# ISP register map
Vendor: Texas Instruments
Peripheral module from a debugger description file (folder omap34xx).
Registers are 32-bit, read-write, reset 0x0 unless marked. A register's access mark holds for its fields unless they carry their own. Offsets are as the file gives them; lines under a group give offsets from that group; [hi:lo] are bit positions; {n}, {i} and the like mark numbered series; 'fields as' and 'values as' point back to an identical list; <NAME> marks a mode.

## ISP
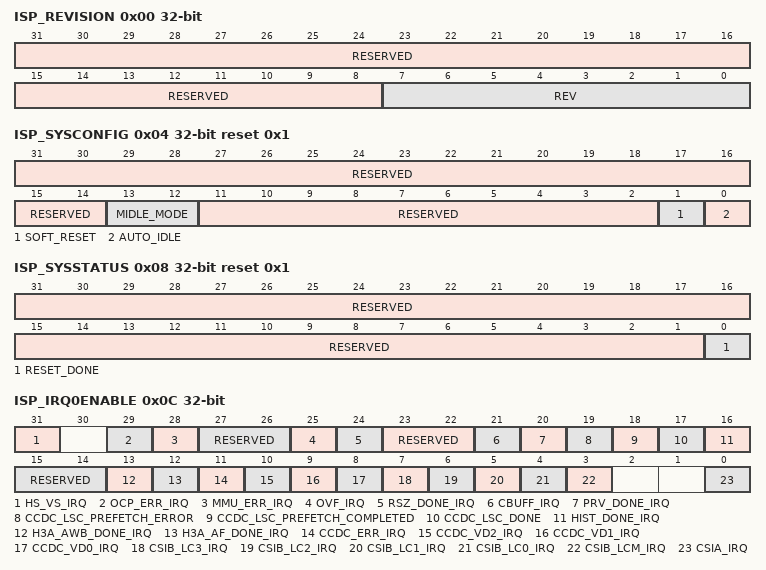
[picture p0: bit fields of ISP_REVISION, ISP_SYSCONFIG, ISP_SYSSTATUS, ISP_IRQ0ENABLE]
0x00 ISP_REVISION ro (reset mask 0xFFFFFF00) — ISP REVISION REGISTER This register contains the IP revision code in binary coded digital. For example, we have: 0x01 = revision 0.1 and 0x21 = revision 2.1
  [31:8] RESERVED — Write 0s for future compatibility.Reads returns 0.
  [7:0] REV — IP revision. [7:4] major revision[3:0] minor revision
0x04 ISP_SYSCONFIG reset 0x1 — ISP SYSTEM CONFIGURATION REGISTER
  [31:14] RESERVED — Write 0s for future compatibility.Reads returns 0.
  [13:12] MIDLE_MODE — Master interface power management, MSTANDBY/WAIT protocol.
    0=Force-standby: the MSTANDBY signal is only asserted to the power and reset clock manager when the module is disabled; 1=No-standby: the MSTANDBY signal is never asserted to the power and reset clock manager; 2=Smart-standby: the MSTANDBY signal is asserted to the power and reset clock manager based on the internal activity of the module. The ISP clocks are not disabled during smart standby.
  [11:2] RESERVED — Write 0s for future compatibility.Reads returns 0.
  [1] SOFT_RESET — Software reset. Set the bit to 1 to trigger the module reset. The bit is automatically reset be the HW. During reads return 0.
    0=Normal mode; 1=The module is reset
  [0] AUTO_IDLE — Internal interconnect and functional clock gating strategy
    0=Interconnect and functional clock is free running; 1=Automatic interface clock gating strategy is applied based on the Interconnect interface activity for interface clock and on the functional activity for functional clocks
0x08 ISP_SYSSTATUS ro reset 0x1 — ISP SYSTEM STATUS REGISTER
  [31:1] RESERVED — Write 0s for future compatibility.Reads returns 0.
  [0] RESET_DONE — Internal reset monitoring
    0=Internal module reset is ongoing; 1=Reset completed
0x0C ISP_IRQ0ENABLE — INTERRUPT ENABLE REGISTER TO MCU. IRQ0 STATUS LINE. The same events are mapped in IRQ1. However, one event should be mapped to only one target.
  [31] HS_VS_IRQ — HS or VS synchro event This event is triggered if a rising or falling edge is detected on the HS or VS signal. The rising or falling edge and the HS or VS signal selection is chosen with the ISP_CTRL.SYNC_DTECT bit field.
    0=Event is masked; 1=Event generates an interrupt when it occurs
  [29] OCP_ERR_IRQ — ISP Interconnect error. This event is triggered when an Interconnect error occurs: SResp = ERR.
    values as HS_VS_IRQ
  [28] MMU_ERR_IRQ — MMU error.
    values as HS_VS_IRQ
  [27:26] RESERVED — Write 0s for future compatibility.Reads returns 0.
  [25] OVF_IRQ — Central Resource SBL overflow This event is triggered when one of the buffer in the central resource SBL overflows.
    values as HS_VS_IRQ
  [24] RSZ_DONE_IRQ — RESIZER module - resizer processing done event. This event is triggered at the end of the frame when the processing is completed for the current frame.
    values as HS_VS_IRQ
  [23:22] RESERVED — Write 0s for future compatibility.Reads returns 0.
  [21] CBUFF_IRQ — Circular buffer interrupt
    values as HS_VS_IRQ
  [20] PRV_DONE_IRQ — PREVIEW module - processing done event. This event is triggered at the end of the frame when the processing is completed for the current frame.
    values as HS_VS_IRQ
  [19] CCDC_LSC_PREFETCH_ERROR — The prefetch error indicates when the gain table was read to slowly from SDRAM. When this event is pending the module goes into transparent mode (output=input). Normal operation can be resumed at the start of the next frame after1) clearing this event2) disabling the LSC module3) enabling it
    values as HS_VS_IRQ
  [18] CCDC_LSC_PREFETCH_COMPLETED — Indicates current state of the prefetch buffer. Can be used to start sending the data once the buffer is full to minimize the risk of an underflow. This event is triggered when the buffer contains 3 full paxel rows. It can be used to minimize buffer underflow risks.
    values as HS_VS_IRQ
  [17] CCDC_LSC_DONE — The event is triggered when the internal state of LSCtoggles from BUSY to IDLE.
    values as HS_VS_IRQ
  [16] HIST_DONE_IRQ — HIST module - processing done event. This event is triggered at the end of the frame when the processing is completed for the current frame.
    values as HS_VS_IRQ
  [15:14] RESERVED — Write 0s for future compatibility.Reads returns 0.
  [13] H3A_AWB_DONE_IRQ — H3A module - auto exposure and auto white balance processing done event. This event is triggered at the end of the frame when the processing is completed for the current frame.
    values as HS_VS_IRQ
  [12] H3A_AF_DONE_IRQ — H3A module - autofocus processing done event. This event is triggered at the end of the frame when the processing is completed for the current frame.
    values as HS_VS_IRQ
  [11] CCDC_ERR_IRQ — CCDC module - faulty pixel correction memory underflow
    values as HS_VS_IRQ
  [10] CCDC_VD2_IRQ — CCDC module - programmable event 2
    values as HS_VS_IRQ
  [9] CCDC_VD1_IRQ — CCDC module - programmable event 1.
    values as HS_VS_IRQ
  [8] CCDC_VD0_IRQ — CCDC module - programmable event 0.
    values as HS_VS_IRQ
  [7] CSIB_LC3_IRQ — CSI1/CCP2B receiver module - event on logical channel 3.
    values as HS_VS_IRQ
  [6] CSIB_LC2_IRQ — CSI1/CCP2B receiver module - event on logical channel 2
    values as HS_VS_IRQ
  [5] CSIB_LC1_IRQ — CSI1/CCP2B receiver module - event on logical channel 1
    values as HS_VS_IRQ
  [4] CSIB_LC0_IRQ — CSI1/CCP2B receiver module - event on logical channel 0
    values as HS_VS_IRQ
  [3] CSIB_LCM_IRQ — CSI1/CCP2B RECEIVER module - event on memory channel.
    values as HS_VS_IRQ
  [0] CSIA_IRQ — CSIA_RECEIVER module event.
    values as HS_VS_IRQ
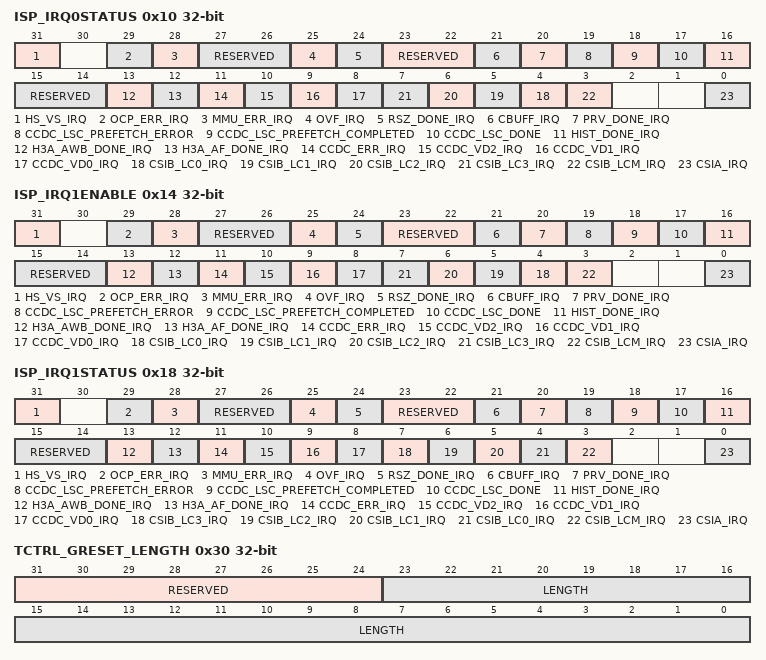
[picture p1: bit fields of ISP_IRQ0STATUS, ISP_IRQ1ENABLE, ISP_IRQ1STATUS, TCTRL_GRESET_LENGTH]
0x10 ISP_IRQ0STATUS access not given — INTERRUPT STATUS REGISTER TO MCU. IRQ0 STATUS LINE.
  [31] HS_VS_IRQ — HS or VS synchro event READS:0: event is false1: event is true WRITES0: status bit unchanged1: status bit reset (access R/W/1toClr)
  [29] OCP_ERR_IRQ — ISP Interconnect error. READS:0: event is false1: event is true WRITES0: status bit unchanged1: status bit reset (access R/W/1toClr)
  [28] MMU_ERR_IRQ — MMU error. If event is true, one needs to read the MMU_IRQSTATUS register to know the event source. Write in MMU_IRQSTATUS to clear the bit. READS:0: event is false1: event is true (access R/W/1toClr)
  [27:26] RESERVED — Write 0s for future compatibility.Reads returns 0. (access R/W/1toClr)
  [25] OVF_IRQ — Central Resource SBL overflow If event is true, one needs to check the SBL_PCR register to know the source. One needs to clear the SBL_PCR register first before clearing this bit. READS:0: event is false1: event is true WRITES0: status bit unchanged1: status bit reset (access R/W/1toClr)
  [24] RSZ_DONE_IRQ — RESIZER module - resizer processing done event. READS:0: event is false1: event is true WRITES0: status bit unchanged1: status bit reset (access R/W/1toClr)
    values as ISP_IRQ0ENABLE.HS_VS_IRQ
  [23:22] RESERVED — Write 0s for future compatibility.Reads returns 0. (access R/W/1toClr)
  [21] CBUFF_IRQ — A circular buffer event is pending. Check submodule's interrupt status register. READS:0: event is false1: event is true WRITES0: status bit unchanged1: status bit reset (access R/W/1toClr)
  [20] PRV_DONE_IRQ — PREVIEW module - processing done event. READS:0: event is false1: event is true WRITES0: status bit unchanged1: status bit reset (access R/W/1toClr)
  [19] CCDC_LSC_PREFETCH_ERROR — The prefetch error indicates when the gain table was read to slowly from SDRAM. READS:0: event is false1: event is true WRITES0: status bit unchanged1: status bit reset (access R/W/1toClr)
  [18] CCDC_LSC_PREFETCH_COMPLETED — Indicates current state of the prefetch buffer. READS:0: event is false1: event is true WRITES0: status bit unchanged1: status bit reset (access R/W/1toClr)
  [17] CCDC_LSC_DONE — The event is triggered when the internal state of LSC toggles from BUSY to IDLE. READS:0: event is false1: event is true WRITES0: status bit unchanged1: status bit reset (access R/W/1toClr)
  [16] HIST_DONE_IRQ — HIST module - processing done event.READS:0: event is false1: event is true WRITES0: status bit unchanged1: status bit reset (access R/W/1toClr)
  [15:14] RESERVED — Write 0s for future compatibility.Reads returns 0. (access R/W/1toClr)
  [13] H3A_AWB_DONE_IRQ — H3A module - auto exposure and auto white balance processing done event. READS:0: event is false1: event is true WRITES0: status bit unchanged1: status bit reset (access R/W/1toClr)
  [12] H3A_AF_DONE_IRQ — H3A module - autofocus processing done event. READS:0: event is false1: event is true WRITES0: status bit unchanged1: status bit reset (access R/W/1toClr)
  [11] CCDC_ERR_IRQ — CCDC module - faulty pixel correction memory underflow If event is true, one needs to clear the CCDC_FPC.FPERR bit first before clearing this bit. READS:0: event is false1: event is true WRITES0: status bit unchanged1: status bit reset (access R/W/1toClr)
  [10] CCDC_VD2_IRQ — CCDC module - programmable event 2 READS:0: event is false1: event is true WRITES0: status bit unchanged1: status bit reset (access R/W/1toClr)
  [9] CCDC_VD1_IRQ — CCDC module - programmable event 1. READS:0: event is false1: event is true WRITES0: status bit unchanged1: status bit reset (access R/W/1toClr)
  [8] CCDC_VD0_IRQ — CCDC module - programmable event 0. READS:0: event is false1: event is true WRITES0: status bit unchanged1: status bit reset (access R/W/1toClr)
  [n+4] CSIB_LC{n}_IRQ (n=0..3) — CSI1/CCP2B receiver module - event on logical channel {n}. READS:0: event is false1: event is true WRITES0: status bit unchanged1: status bit reset (access R/W/1toClr)
  [3] CSIB_LCM_IRQ — CSI1/CCP2B receiver module - event on memory channel. READS:0: event is false1: event is true WRITES0: status bit unchanged1: status bit reset (access R/W/1toClr)
  [0] CSIA_IRQ — CSIA RECEIVER module event. If event is true, one needs to read the CSIA_IRQSTATUS register to know the event source. Write in CSIA_IRQSTATUS to clear the bit. READS:0: event is false1: event is true WRITES0: status bit unchanged1: status bit reset (access R/W/1toClr)
0x14 ISP_IRQ1ENABLE — INTERRUPT ENABLE REGISTER TO DSP. IRQ1 STATUS LINE. The same events are mapped in IRQ0. However, one event should be mapped to only one target.
  [31] HS_VS_IRQ — HS or VS synchro event This event is triggered if a rising or falling edge is detected on the HS or VS signal. The rising or falling edge and the HS or VS signal selection is chosen with the ISP_CTRL.SYNC_DTECT bit field.
    values as ISP_IRQ0ENABLE.HS_VS_IRQ
  [29] OCP_ERR_IRQ — ISP Interconnect error. This event is triggered when an Interconnect error occurs: SResp = ERR.
    values as ISP_IRQ0ENABLE.HS_VS_IRQ
  [28] MMU_ERR_IRQ — MMU error.
    values as ISP_IRQ0ENABLE.HS_VS_IRQ
  [27:26] RESERVED — Write 0s for future compatibility.Reads returns 0.
  [25] OVF_IRQ — Central Resource SBL overflow This event is triggered when one of the buffer in the central resource SBL overflows.
    values as ISP_IRQ0ENABLE.HS_VS_IRQ
  [24] RSZ_DONE_IRQ — RESIZER module - resizer processing done event. This event is triggered at the end of the frame when the processing is completed for the current frame.
    values as ISP_IRQ0ENABLE.HS_VS_IRQ
  [23:22] RESERVED — Write 0s for future compatibility.Reads returns 0.
  [21] CBUFF_IRQ — Circular buffer interrupt
    values as ISP_IRQ0ENABLE.HS_VS_IRQ
  [20] PRV_DONE_IRQ — PREVIEW module - processing done event. This event is triggered at the end of the frame when the processing is completed for the current frame.
    values as ISP_IRQ0ENABLE.HS_VS_IRQ
  [19] CCDC_LSC_PREFETCH_ERROR — The prefetch error indicates when the gain table was read to slowly from SDRAM. When this event is pending the module goes into transparent mode (output=input). Normal operation can be resumed at the start of the next frame after1) clearing this event2) disabling the LSC module3) enabling it
    values as ISP_IRQ0ENABLE.HS_VS_IRQ
  [18] CCDC_LSC_PREFETCH_COMPLETED — Indicates current state of the prefetch buffer. Can be used to start sending the data once the buffer is full to minimize the risk of an underflow. This event is triggered when the buffer contains 3 full paxel rows. It can be used to minimize buffer underflow risks.
    values as ISP_IRQ0ENABLE.HS_VS_IRQ
  [17] CCDC_LSC_DONE — The event is triggered when the internal state of LSCtoggles from BUSY to IDLE.
    values as ISP_IRQ0ENABLE.HS_VS_IRQ
  [16] HIST_DONE_IRQ — HIST module - processing done event. This event is triggered at the end of the frame when the processing is completed for the current frame.
    values as ISP_IRQ0ENABLE.HS_VS_IRQ
  [15:14] RESERVED — Write 0s for future compatibility.Reads returns 0.
  [13] H3A_AWB_DONE_IRQ — H3A module - auto exposure and auto white balance processing done event. This event is triggered at the end of the frame when the processing is completed for the current frame.
    values as ISP_IRQ0ENABLE.HS_VS_IRQ
  [12] H3A_AF_DONE_IRQ — H3A module - autofocus processing done event. This event is triggered at the end of the frame when the processing is completed for the current frame.
    values as ISP_IRQ0ENABLE.HS_VS_IRQ
  [11] CCDC_ERR_IRQ — CCDC module - faulty pixel correction memory underflow
    values as ISP_IRQ0ENABLE.HS_VS_IRQ
  [10] CCDC_VD2_IRQ — CCDC module - programmable event 2
    values as ISP_IRQ0ENABLE.HS_VS_IRQ
  [9] CCDC_VD1_IRQ — CCDC module - programmable event 1.
    values as ISP_IRQ0ENABLE.HS_VS_IRQ
  [8] CCDC_VD0_IRQ — CCDC module - programmable event 0.
    values as ISP_IRQ0ENABLE.HS_VS_IRQ
  [n+4] CSIB_LC{n}_IRQ (n=0..3) — CSI1/CCP2B receiver module - event on logical channel {n}.
    values as ISP_IRQ0ENABLE.HS_VS_IRQ
  [3] CSIB_LCM_IRQ — CSI1/CCP2B receiver module - event on memory channel.
    values as ISP_IRQ0ENABLE.HS_VS_IRQ
  [0] CSIA_IRQ — CSI2A RECEIVER module event.
    values as ISP_IRQ0ENABLE.HS_VS_IRQ
0x18 ISP_IRQ1STATUS access not given — INTERRUPT STATUS REGISTER TO DSP. IRQ1 STATUS LINE.
  [31] HS_VS_IRQ — HS or VS synchro event READS:0: event is false1: event is true WRITES0: status bit unchanged1: status bit reset (access R/W/1toClr)
  [29] OCP_ERR_IRQ — ISP Interconnect error. READS:0: event is false1: event is true WRITES0: status bit unchanged1: status bit reset (access R/W/1toClr)
  [28] MMU_ERR_IRQ — MMU error. If event is true, one needs to read the MMU_IRQSTATUS register to know the event source. Write in MMU_IRQSTATUS to clear the bit. READS:0: event is false1: event is true (access R/W/1toClr)
  [27:26] RESERVED — Write 0s for future compatibility.Reads returns 0. (access R/W/1toClr)
  [25] OVF_IRQ — Central Resource SBL overflow If event is true, one needs to check the SBL_PCR register to know the source. One needs to clear the SBL_PCR register first before clearing this bit. READS:0: event is false1: event is true WRITES0: status bit unchanged1: status bit reset (access R/W/1toClr)
  [24] RSZ_DONE_IRQ — RESIZER module - resizer processing done event. READS:0: event is false1: event is true WRITES0: status bit unchanged1: status bit reset (access R/W/1toClr)
    values as ISP_IRQ0ENABLE.HS_VS_IRQ
  [23:22] RESERVED — Write 0s for future compatibility.Reads returns 0. (access R/W/1toClr)
  [21] CBUFF_IRQ — A circular buffer event is pending. Check submodule's interrupt status register. READS:0: event is false1: event is true WRITES0: status bit unchanged1: status bit reset (access R/W/1toClr)
  [20] PRV_DONE_IRQ — PREVIEW module - processing done event. READS:0: event is false1: event is true WRITES0: status bit unchanged1: status bit reset (access R/W/1toClr)
  [19] CCDC_LSC_PREFETCH_ERROR — The prefetch error indicates when the gain table was read to slowly from SDRAM. READS:0: event is false1: event is true WRITES0: status bit unchanged1: status bit reset (access R/W/1toClr)
  [18] CCDC_LSC_PREFETCH_COMPLETED — Indicates current state of the prefetch buffer. READS:0: event is false1: event is true WRITES0: status bit unchanged1: status bit reset (access R/W/1toClr)
  [17] CCDC_LSC_DONE — The event is triggered when the internal state of LSC toggles from BUSY to IDLE. READS:0: event is false1: event is true WRITES0: status bit unchanged1: status bit reset (access R/W/1toClr)
  [16] HIST_DONE_IRQ — HIST module - processing done event.READS:0: event is false1: event is true WRITES0: status bit unchanged1: status bit reset (access R/W/1toClr)
  [15:14] RESERVED — Write 0s for future compatibility.Reads returns 0. (access R/W/1toClr)
  [13] H3A_AWB_DONE_IRQ — H3A module - auto exposure and auto white balance processing done event. READS:0: event is false1: event is true WRITES0: status bit unchanged1: status bit reset (access R/W/1toClr)
  [12] H3A_AF_DONE_IRQ — H3A module - autofocus processing done event. READS:0: event is false1: event is true WRITES0: status bit unchanged1: status bit reset (access R/W/1toClr)
  [11] CCDC_ERR_IRQ — CCDC module - faulty pixel correction memory underflow If event is true, one needs to clear the CCDC_FPC.FPERR bit first before clearing this bit. READS:0: event is false1: event is true WRITES0: status bit unchanged1: status bit reset (access R/W/1toClr)
  [10] CCDC_VD2_IRQ — CCDC module - programmable event 2 READS:0: event is false1: event is true WRITES0: status bit unchanged1: status bit reset (access R/W/1toClr)
  [9] CCDC_VD1_IRQ — CCDC module - programmable event 1. READS:0: event is false1: event is true WRITES0: status bit unchanged1: status bit reset (access R/W/1toClr)
  [8] CCDC_VD0_IRQ — CCDC module - programmable event 0. READS:0: event is false1: event is true WRITES0: status bit unchanged1: status bit reset (access R/W/1toClr)
  [7] CSIB_LC3_IRQ — CSI1/CCP2B receiver module - event on logical channel 3. READS:0: event is false1: event is true WRITES0: status bit unchanged1: status bit reset (access R/W/1toClr)
  [6] CSIB_LC2_IRQ — CSI1/CCP2B receiver module - event on logical channel 2 . READS:0: event is false1: event is true WRITES0: status bit unchanged1: status bit reset (access R/W/1toClr)
  [5] CSIB_LC1_IRQ — CSI1/CCP2B receiver module - event on logical channel 1. READS:0: event is false1: event is true WRITES0: status bit unchanged1: status bit reset (access R/W/1toClr)
  [4] CSIB_LC0_IRQ — CSI1/CCP2B receiver module - event on logical channel 0. READS:0: event is false1: event is true WRITES0: status bit unchanged1: status bit reset (access R/W/1toClr)
  [3] CSIB_LCM_IRQ — CSI1/CCP2B receiver module - event on memory channel. READS:0: event is false1: event is true WRITES0: status bit unchanged1: status bit reset (access R/W/1toClr)
  [0] CSIA_IRQ — CSIA RECEIVER module event. If event is true, one needs to read the CSIA_IRQSTATUS register to know the event source. Write in CSIA_IRQSTATUS to clear the bit. READS:0: event is false1: event is true WRITES0: status bit unchanged1: status bit reset (access R/W/1toClr)
0x30 TCTRL_GRESET_LENGTH — TIMING CONTROL - GLOBAL SHUTTER LENGTH REGISTER This register is used by the TIMING CTRL module to generate the cam_global_reset signal.
  [31:24] RESERVED — Write 0s for future compatibility.Reads returns 0.
  [23:0] LENGTH — Sets the length of the cam_global_reset signal assertion in cycles of the CNTCLK clock. The CNTCLK frequency is generated with the TCTRL_CTRL.DIVC bit field. After signal assertion, the TCTRL_CTRL.GRESETEN bit is automatically cleared. The possible values are 0 to 2^24-1 cycles. The polarity of the cam_global_reset signal is set by the TCTRL_CTRL.GRESETPOL bit.
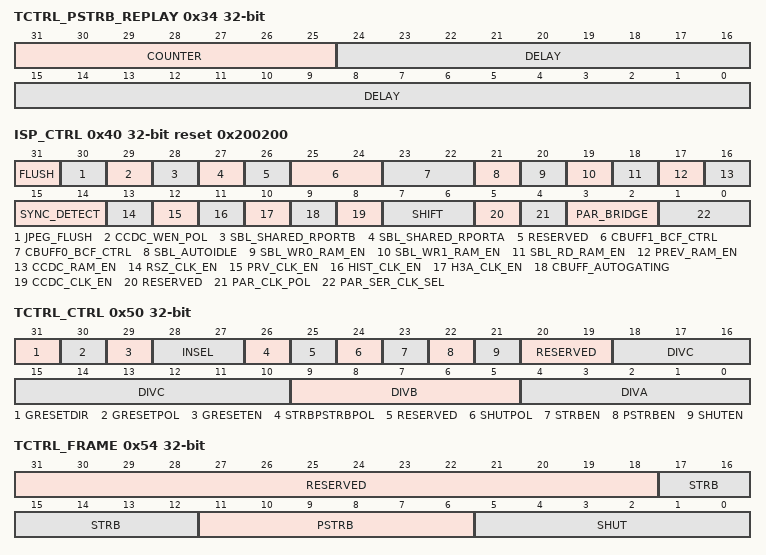
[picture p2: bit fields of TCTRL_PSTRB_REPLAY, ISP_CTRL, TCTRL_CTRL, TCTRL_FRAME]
0x34 TCTRL_PSTRB_REPLAY — TIMING CONTROL - PRESTROBE REPLAY REGISTER This register is used by the TIMING CTRL module to generate the prestrobe signal.
  [31:25] COUNTER — Sets the number of PRESTROBE pulses after the original pulse. If this bit is set to 0, the PRESTROBE signal behavior is only controlled by TCTRL_FRAME.STRB, TCTRL_PSTRB_DELAY and TCTRL_PSTRB_LENGTH. If TCTRL_PSTRB_LENGTH=0, there is no replay. This bit is useful when one wants to enable red-eye removal.
  [24:0] DELAY — Sets the delay for the PRESTROBE signal re-assertion in cycles of the CNTCLK clock. The CNTCLK frequency is generated with theTCTRL_CTRL.DIVC bit field. The possible values are 0 to 2^25-1 cycles. If TCTRL_PSTRB_LENGTH=0, there is no replay. This bit field must not be set to 0 if the COUNTER is set to a value different of 0. This bit is useful when one wants to enable red-eye removal.
0x40 ISP_CTRL reset 0x200200 — CONTROL REGISTER After reset, the parallel interface is selected and only the CCDC module data write port is enabled.
  [31] FLUSH — CCDC memory flush Writing 1 in this bit flushes the CCDC memories in the central resource SBL. The SBL memories are always flushed by the end of frame. However, there are cases where the end of frame cannot be detected.
  [30] JPEG_FLUSH — JPEG flush When a camera module outputs a JPEG bit stream, this bit must be set because the bit stream length may not be a multiple of 32 bits. Enabling this bit ensures that no data stay in the design internal FIFOS.
  [29] CCDC_WEN_POL — Sets the polarity of the CCDC WEN bit.
    0=Active low; 1=Active high
  [28] SBL_SHARED_RPORTB — Controls SBL shared read port B access
    0=Read port used by preview module dark frame read; 1=Read port used by CCDC module lens-shading compensation data read
  [27] SBL_SHARED_RPORTA — Controls SBL shared read port A access
    0=Read port used by preview module data read; 1=Read port used by CSI1 module data read
  [26] RESERVED — Write 0s for future compatibility.Reads returns 0.
  [25:24] CBUFF1_BCF_CTRL — Bandwidth control feedback loop configuration register
    0=Disabled; 1=The BCF signal of CBUFF1 stalls the response phase of the CSIb OCP read master port; 2=The BCF signal of CBUFF1 stalls the request phase of the CSIb OCP read master port; 3=The BCF signal of CBUFF1 stalls the request and response phase of the CSIb OCP read master port
  [23:22] CBUFF0_BCF_CTRL — Bandwidth control feedback loop configuration register
    0=Disabled; 1=The BCF signal of CBUFF0 stalls the response phase of the CSIb OCP read master port; 2=The BCF signal of CBUFF0 stalls the request phase of the CSIb OCP read master port; 3=The BCF signal of CBUFF0 stalls the request and response phase of the CSIb OCP read master port
  [21] SBL_AUTOIDLE — Sets the SBL autoidle mode
    0=Disabled; 1=Enabled
  [20] SBL_WR0_RAM_EN — This bit controls the SBL module WRITE0 RAM used by the RESIZER module. If the RESIZER module is disabled, this bit should be set to 0 to save power.
    0=RAM is disabled; 1=RAM is enabled
  [19] SBL_WR1_RAM_EN — This bit controls the SBL module WRITE1 RAM. If the RESIZER module is the only module enabled to perform memory to memory resize operations, this bit should be set to 0 to save power.
    0=RAM is disabled; 1=RAM is enabled
  [18] SBL_RD_RAM_EN — This bit controls the SBL module READ RAM. If no read requests are generated, this bit should be set to 0 to save power.
    0=RAM is disabled; 1=RAM is enabled
  [17] PREV_RAM_EN — This bit controls the PREVIEW module RAM. If the PREVIEW module is not used, this bit should be set to 0 to save power.
    0=RAM is disabled; 1=RAM is enabled
  [16] CCDC_RAM_EN — This bit controls the CCDC module RAM. If the CCDC module is not used, the bit should be set to 0 to save power.
    0=RAM is disabled; 1=RAM is enabled
  [15:14] SYNC_DETECT — HS or VS synchronization signal detection It is sometimes necessary to detect the rising or falling edge of the horizontal and vertical synchro signals. When such event is detected, an interrupt is triggered if ISP_IRQ0ENABLE.HS_VS_IRQ = 1 or ISP_IRQ0ENABLE.HS_VS_IRQ = 1.
    0=HS falling edge; 1=HS rising edge; 2=VS falling edge; 3=VS rising edge
  [13] RSZ_CLK_EN — RSZ module clock enable. This bit controls the clock distribution to the RSZ module.
    0=Disable clock. The module is not active. However, accesses on the module slave port to configure it are still possible.; 1=Enable clock. The module is fully functional.
  [12] PRV_CLK_EN — PRV module clock enable. This bit controls the clock distribution to the PRV module.
    values as RSZ_CLK_EN
  [11] HIST_CLK_EN — HIST module clock enable. This bit controls the clock distribution to the HIST module.
    values as RSZ_CLK_EN
  [10] H3A_CLK_EN — H3A module clock enable. This bit controls the clock distribution to the H3A module.
    values as RSZ_CLK_EN
  [9] CBUFF_AUTOGATING — CBUFF module autogating feature control
    0=CBUFF autogating feature is disabled. The CBUFF internal clock is free running.; 1=CBUFF autogating feature is enabled. The CBUFF internal clock is only enabled when it is requested by the CBUFF module.
  [8] CCDC_CLK_EN — CCDC module clock enable. This bit controls the clock distribution to the CCDC module.
    values as RSZ_CLK_EN
  [7:6] SHIFT — Data lane shifter The parallel interface is a 12-bit interface,
    0=No shift. CAMEXT[13:0] - CAM [13:0]; 1=Shift by 2. CAMEXT[13:2] - CAM [11:0]; 2=Shift by 4 CAMEXT[13:4] - CAM [9:0]; 3=Shift by 6 CAMEXT[13:6] - CAM [7:0]
  [5] RESERVED — Write 0s for future compatibility.Reads returns 0.
  [4] PAR_CLK_POL — This bit sets the pixel clock polarity on the parallel interface. The pixel clock is used for latching the pixel data into the CCDC module.
    0=Clock not inverted. The data are sampled on the rising edge of the clock.; 1=Clock inverted. The data are sampled on the falling edge of the clock.
  [3:2] PAR_BRIDGE — This bit field controls the 8 to 16-bit bridge at the input of the CCDC module.
    0=The bridge is disabled: no conversion; 2=The bridge is enabled. The first byte is written to cam_d[7:0], the second byte is written to cam_d[15:8]; 3=The bridge is enabled. The first byte is written to cam_d[15:8], the second byte is written to cam_d[7:0]
  [1:0] PAR_SER_CLK_SEL — Selects the serial or parallel interface as the input to the preview hardware.
    0=Selects the 12-bit parallel interface as the input to the CCDC module; 1=Selects the CSIA serial interface as the input to the CCDC module; 2=Selects the CSIB serial interface as the input to the CCDC module
0x50 TCTRL_CTRL — TIMING CONTROL - CONTROL REGISTER
  [31] GRESETDIR — Sets the direction of the cam_global_reset signal. 0x0: INPUT. cam_global_reset is an input to the TIMING CONTROL module. cam_global_reset is externally generated. 0x1: OUTPUT. cam_global_reset is an output of the TIMING CONTROL module. cam_global_reset is internally generated. If GRESETEN is set to 1, the internally generated cam_global_reset triggers the generation of the PRESTROBE, STROBE and SHUTTER signals. The frame counters are ignored.
  [30] GRESETPOL — Sets the polarity of the global reset signal: cam_global_reset. It applies whatever the direction of the cam_global_reset signal: input or output.0x0: active high0x1: active low
  [29] GRESETEN — Triggers the generation of the cam_global_reset signal. The signal is asserted immediately. If enabled, the cam_global_reset signal is asserted forTCTRL_GRESET_LENGTH cycles. After the signal assertion, the enable bit is automatically cleared to 0. The polarity of the cam_global_reset signal is set with TCTRL_CTRL.GRESETPOL. Enabling this bit triggers the generation of the cam_shutter and cam_strobe signals (if previously enabled). The frame counters must be set to 0 when this bit is set to 1 and GRESETDIR is set a OUTPUT.
  [28:27] INSEL — Sets the mode that triggers the SHUTTER, PRESTROBE and STROBE signals.
    0=Video Port. The VS sync pulse at the input of the CCDC module is used to count the frames.The source of the VS pulse is selected by the [1:0] PAR_SER_CLK_SEL register.; 1=CSIA interface. The frame start code (FSC) and frame end code (FEC) sync codes are used to count the frames.; 2=CSIB interface. The frame start code (FSC) and frame end code (FEC) sync codes are used to count the frames.; 3=GRESET. The cam_global_reset input signal triggers the SHUTTER, PRESTROBE and STROBE signals. In this mode, there are no frame counters. The delay counters start decrementing as soon as the cam_global_reset signal is asserted. The polarity of the cam_global_reset signal is set with.GRESETPOL.
  [26] STRBPSTRBPOL — Sets the polarity of the strobe and prestrobe signals.
    0=Active high; 1=Active low
  [25] RESERVED — Write 0s for future compatibility.Reads returns 0.
  [24] SHUTPOL — Sets the polarity of the mechanical shutter signal: cam_shutter
    0=Active high; 1=Active low
  [23] STRBEN — Flash strobe signal enable. If enabled, the STROBE signal is asserted afterTCTRL_FRAME.STRB frames have been received and a delay of TCTRL_STRB_DELAY cycles have passed. The STROBE signal is asserted for TCTRL_STRB_LENGTH cycles. After the signal assertion, the enable bit is automatically cleared to 0. This signal must not be disabled by software.
  [22] PSTRBEN — Flash prestrobe signal enable. If enabled, the PRESTROBE signal is asserted afterTCTRL_FRAME.PSTRB frames have been received and a delay of TCTRL_PSTRB_DELAY cycles have passed. The PRESTROBE signal is asserted for TCTRL_PSTRB_LENGTH cycles. After the signal assertion, the enable bit is automatically cleared to 0. This signal must not be disabled by software.
  [21] SHUTEN — Mechanical shutter signal enable. If enabled, the SHUTTER signal is asserted afterTCTRL_FRAME.SHUT frames have been received and a delay of TCTRL_SHUT_DELAY cycles have passed. The SHUTTER signal is asserted for TCTRL_SHUT_LENGTH cycles. After the signal assertion, the enable bit is automatically cleared to 0. This signal must not be disabled by software.
  [20:19] RESERVED — Write 0s for future compatibility.Reads returns 0.
  [18:10] DIVC — Sets the clock divisor value for the CNTCLK clock generation based on the CAM_MCLK input clock. CNTCLK is an internal clock used by the TIMING CTRL module counters. Usually, CNTCLK = CAM_MCLK/DIVC, except for some particular values shown hereafter.
    0=No clock. CNTCLK is gated.
  [9:5] DIVB — Sets the clock divisor value for the cam_xclkb clock generation based on the CAM_MCLK input clock. Usually, cam_xclkb = CAM_MCLK/DIVB, except for some particular values shown hereafter. This bit field is not reset by a soft reset; a hard reset is required. It enables to keep the clock configuration stable through a soft reset.
    0=cam_xclkb = stable low level. Divider disabled.; 1=cam_xclkb = stable high level. Divider disabled.; 31=cam_xclkb = cam_xclk. Bypass.
  [4:0] DIVA — Sets the clock divisor value for the cam_xclka clock generation based on the CAM_MCLK input clock. Usually, cam_xclka = CAM_MCLK/DIVA, except for some particular values shown hereafter. This bit field is not reset by a soft reset; a hard reset is required. It enables to keep the clock configuration stable through a soft reset.
    0=cam_xclka = stable low level. Divider disabled.; 1=cam_xclka = stable high level. Divider disabled.; 31=cam_xclka = cam_xclk. Bypass.
0x54 TCTRL_FRAME — TIMING CONTROL - FRAME REGISTER This register is used by the TIMING CTRL module to generate the SHUTTER, PRESTROBE and STROBE signals.
  [31:18] RESERVED — Write 0s for future compatibility.Reads returns 0.
  [17:12] STRB — Frame counter for the STROBE signal generation. From 0 to 63 frames. This bit field is ignored if TCTRL.INSEL=GRESET.
  [11:6] PSTRB — Frame counter for the PRESTROBE signal generation. From 0 to 63 frames. This bit field is ignored if TCTRL.INSEL=GRESET.
  [5:0] SHUT — Frame counter for the SHUTTER signal generation. From 0 to 63 frames. This bit field is ignored if TCTRL.INSEL=GRESET.
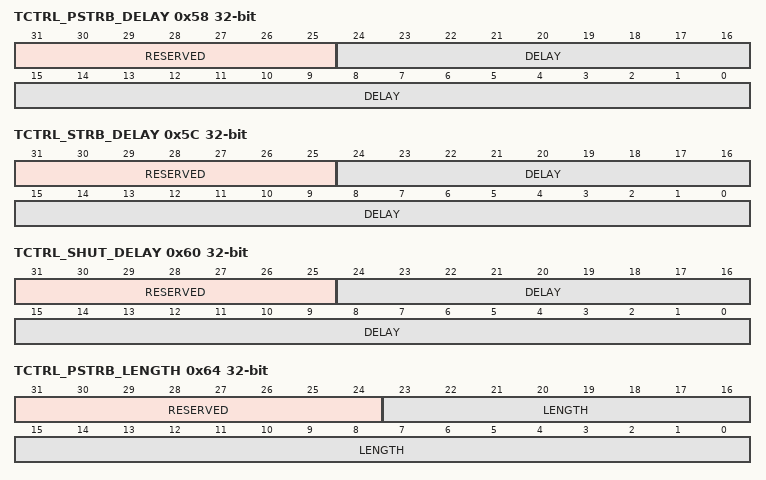
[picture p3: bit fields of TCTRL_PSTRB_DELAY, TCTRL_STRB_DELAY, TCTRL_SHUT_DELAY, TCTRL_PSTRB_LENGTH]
0x58 TCTRL_PSTRB_DELAY — TIMING CONTROL - PRE STROBE DELAY REGISTER This register is used by the TIMING CTRL module to generate the PRESTROBE signal.
  [31:25] RESERVED — Write 0s for future compatibility.Reads returns 0.
  [24:0] DELAY — Sets the delay for the PRESTROBE signal assertion in cycles of the CNTCLK clock. The CNTCLK frequency is generated with theTCTRL_CTRL.DIVC bit field. The possible values are 0 to 2^25-1 cycles.
0x5C TCTRL_STRB_DELAY — TIMING CONTROL - STROBE DELAY REGISTER This register is used by the TIMING CTRL module to generate the STROBE signal.
  [31:25] RESERVED — Write 0s for future compatibility.Reads returns 0.
  [24:0] DELAY — Sets the delay for the cam_strobe signal assertion in cycles of the CNTCLK clock. The CNTCLK frequency is generated with theTCTRL_CTRL.DIVC bit field. The possible values are 0 to 2^25-1 cycles.
0x60 TCTRL_SHUT_DELAY — TIMING CONTROL - SHUTTER DELAY REGISTER This register is used by the TIMING CTRL module to generate the SHUTTER signal.
  [31:25] RESERVED — Write 0s for future compatibility.Reads returns 0.
  [24:0] DELAY — Sets the delay for the cam_shutter signal assertion in cycles of the CNTCLK clock. The CNTCLK frequency is generated with theTCTRL_CTRL.DIVC bit field. The possible values are 0 to 2^25-1 cycles.
0x64 TCTRL_PSTRB_LENGTH — TIMING CONTROL - PRESTROBE LENGTH REGISTER This register is used by the TIMING CTRL module to generate the PRESTROBE signal.
  [31:24] RESERVED — Write 0s for future compatibility.Reads returns 0.
  [23:0] LENGTH — Sets the length of the PRESTROBE signal assertion in cycles of the CNTCLK clock. The CNTCLK frequency is generated with theTCTRL_CTRL.DIVC bit field. After signal assertion, the TCTRL_CTRL.PSTRBEN bit is automatically cleared. The possible values are 0 to 2^24-1 cycles.
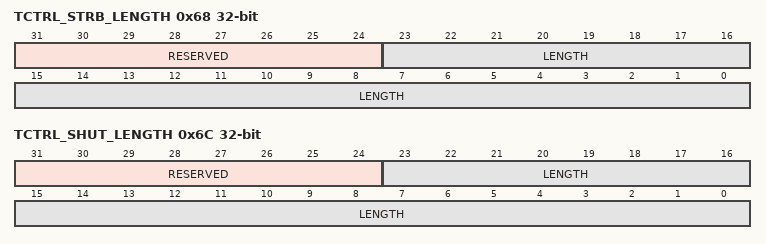
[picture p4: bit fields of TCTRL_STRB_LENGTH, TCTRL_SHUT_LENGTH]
0x68 TCTRL_STRB_LENGTH — TIMING CONTROL - STROBE LENGTH REGISTER This register is used by the TIMING CTRL module to generate the STROBE signal.
  [31:24] RESERVED — Write 0s for future compatibility.Reads returns 0.
  [23:0] LENGTH — Sets the length of the cam_strobe signal assertion in cycles of the CNTCLK clock. The CNTCLK frequency is generated with theTCTRL_CTRL.DIVC bit field. After signal assertion, the TCTRL_CTRL.STRBEN bit is automatically cleared. The possible values are 0 to 2^24-1 cycles.
0x6C TCTRL_SHUT_LENGTH — TIMING CONTROL - SHUTTER LENGTH REGISTER This register is used by the TIMING CTRL module to generate the SHUTTER signal.
  [31:24] RESERVED — Write 0s for future compatibility.Reads returns 0.
  [23:0] LENGTH — Sets the length of the cam_shutter signal assertion in cycles of the CNTCLK clock. The CNTCLK frequency is generated with theTCTRL_CTRL.DIVC bit field. After signal assertion, the TCTRL_CTRL.SHUTEN bit is automatically cleared. The possible values are 0 to 2^24-1 cycles.
